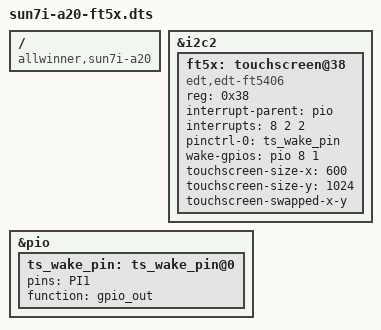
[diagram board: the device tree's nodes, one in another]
/dts-v1/;
/plugin/;

/ {
	compatible = "allwinner,sun7i-a20";

	fragment@0 {
		target = <&i2c2>;
		__overlay__ {
			ft5x: touchscreen@38 {
				compatible = "edt,edt-ft5406";
				reg = <0x38>;
				interrupt-parent = <&pio>;
				interrupts = <8 2 2>;
				pinctrl-names = "default";
				pinctrl-0 = <&ts_wake_pin>;
				wake-gpios = <&pio 8 1 0>;
				touchscreen-size-x = <600>;
				touchscreen-size-y = <1024>;
				touchscreen-swapped-x-y;
			};
		};
	};

	fragment@1 {
		target = <&pio>;
		__overlay__ {
			ts_wake_pin: ts_wake_pin@0 {
				pins = "PI1";
				function = "gpio_out";
			};
		};
	};
};
